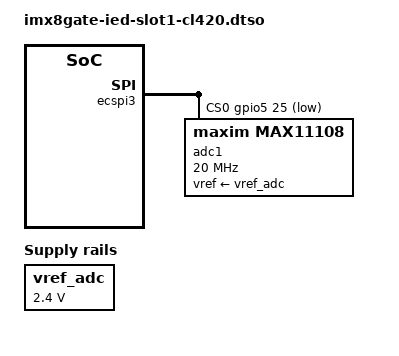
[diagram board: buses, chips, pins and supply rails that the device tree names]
/dts-v1/;
/plugin/;

#include <dt-bindings/gpio/gpio.h>
#include <dt-bindings/interrupt-controller/irq.h>
#include "../freescale/imx8mm-pinfunc.h"

/ {
	fragment@0 {
		target-path = "/";
		__overlay__ {
			vref_adc: regulator-vref-adc {
				compatible = "regulator-fixed";
				regulator-name = "vref_adc";
				regulator-min-microvolt = <2400000>;
				regulator-max-microvolt = <2400000>;
				regulator-always-on;
			};
		};
	};

	fragment@1 {
		target = <&ecspi3>;
		__overlay__ {
			#address-cells = <1>;
			#size-cells = <0>;
			fsl,spi-num-chipselects = <1>;
			pinctrl-names = "default";
			pinctrl-0 = <&pinctrl_ecspi3_sb_iotgimx8_ied &pinctrl_ecspi3_cs_sb_iotgimx8_ied>;
			cs-gpios = <&gpio5 25 GPIO_ACTIVE_LOW>;
			status = "okay";

			adc1: adc@0 {
				compatible = "maxim,max11108";
				reg = <0>;
				vref-supply = <&vref_adc>;
				spi-max-frequency = <20000000>;
				status = "okay";
			};
		};
	};
};
